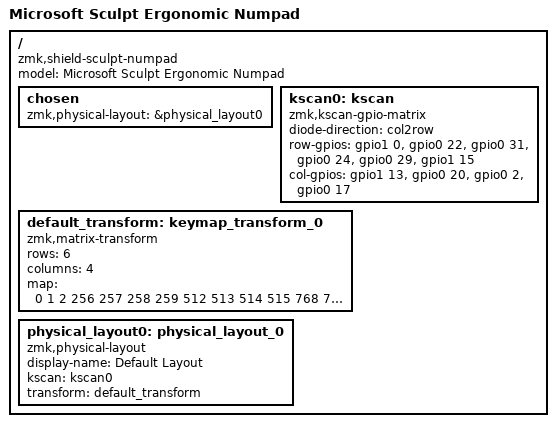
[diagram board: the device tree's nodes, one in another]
/*
 * Microsoft Sculpt Ergonomic Numpad - ZMK Shield Overlay
 * Matrix: 6 rows x 4 cols
 *
 * Row pins (FPC -> nRF52840):
 *   ROW0 = FPC10 -> P1.00
 *   ROW1 = FPC8  -> P0.22
 *   ROW2 = FPC1  -> P0.31
 *   ROW3 = FPC9  -> P0.24
 *   ROW4 = FPC2  -> P0.29
 *   ROW5 = FPC4  -> P1.15
 *
 * Col pins:
 *   COL0 = FPC5 -> P1.13
 *   COL1 = FPC7 -> P0.20
 *   COL2 = FPC3 -> P0.02
 *   COL3 = FPC6 -> P0.17
 *
 * RC(row,col) = (row << 8) + col
 */

#include <dt-bindings/gpio/gpio.h>

/ {
	model = "Microsoft Sculpt Ergonomic Numpad";
	compatible = "zmk,shield-sculpt-numpad";

	chosen {
		zmk,physical-layout = &physical_layout0;
	};

	kscan0: kscan {
		compatible = "zmk,kscan-gpio-matrix";
		diode-direction = "col2row";
		row-gpios = <
			&gpio1 0  GPIO_ACTIVE_HIGH
			&gpio0 22 GPIO_ACTIVE_HIGH
			&gpio0 31 GPIO_ACTIVE_HIGH
			&gpio0 24 GPIO_ACTIVE_HIGH
			&gpio0 29 GPIO_ACTIVE_HIGH
			&gpio1 15 GPIO_ACTIVE_HIGH
		>;
		col-gpios = <
			&gpio1 13 GPIO_ACTIVE_HIGH
			&gpio0 20 GPIO_ACTIVE_HIGH
			&gpio0 2  GPIO_ACTIVE_HIGH
			&gpio0 17 GPIO_ACTIVE_HIGH
		>;
	};

	default_transform: keymap_transform_0 {
		compatible = "zmk,matrix-transform";
		rows = <6>;
		columns = <4>;
		map = <
	0 1 2
	256 257 258 259
	512 513 514 515
	768 769     771
	1024 1025 1026 1027
	        1282 1283
		>;
	};

	physical_layout0: physical_layout_0 {
		compatible = "zmk,physical-layout";
		display-name = "Default Layout";
		kscan = <&kscan0>;
		transform = <&default_transform>;
	};
};
